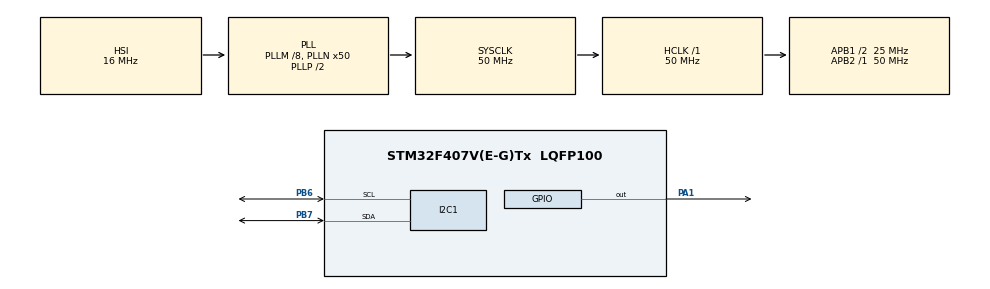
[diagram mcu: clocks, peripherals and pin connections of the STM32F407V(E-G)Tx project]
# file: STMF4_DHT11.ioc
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Mcu.Family=STM32F4
Mcu.Name=STM32F407V(E-G)Tx
Mcu.Package=LQFP100
NVIC.PriorityGroup=NVIC_PRIORITYGROUP_4
PA1.Signal=GPIO_Output
PB6.Mode=I2C
PB6.Signal=I2C1_SCL
PB7.Mode=I2C
PB7.Signal=I2C1_SDA
PH0-OSC_IN.Mode=HSE-External-Oscillator
PH0-OSC_IN.Signal=RCC_OSC_IN
PH1-OSC_OUT.Mode=HSE-External-Oscillator
PH1-OSC_OUT.Signal=RCC_OSC_OUT
ProjectManager.HeapSize=0x200
ProjectManager.StackSize=0x400
ProjectManager.TargetToolchain=MDK-ARM V5.32
RCC.48MHZClocksFreq_Value=25000000
RCC.AHBFreq_Value=50000000
RCC.APB1CLKDivider=RCC_HCLK_DIV2
RCC.APB1Freq_Value=25000000
RCC.APB1TimFreq_Value=50000000
RCC.APB2Freq_Value=50000000
RCC.APB2TimFreq_Value=50000000
RCC.CortexFreq_Value=50000000
RCC.HCLKFreq_Value=50000000
RCC.HSE_VALUE=8000000
RCC.HSI_VALUE=16000000
RCC.PLLM=8
RCC.PLLN=50
RCC.SYSCLKFreq_VALUE=50000000
RCC.SYSCLKSource=RCC_SYSCLKSOURCE_PLLCLK
RCC.VCOOutputFreq_Value=100000000
TIM6.Period=0xffff-1
TIM6.Prescaler=50-1
VP_TIM6_VS_ClockSourceINT.Mode=Enable_Timer
board=custom

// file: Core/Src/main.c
/* USER CODE BEGIN Header */
/**
  ******************************************************************************
  * @file           : main.c
  * @brief          : Main program body
  ******************************************************************************
  * @attention
  *
  * Copyright (c) 2023 STMicroelectronics.
  * All rights reserved.
  *
  * This software is licensed under terms that can be found in the LICENSE file
  * in the root directory of this software component.
  * If no LICENSE file comes with this software, it is provided AS-IS.
  *
  ******************************************************************************
  */
/* USER CODE END Header */
#include "main.h"

/* USER CODE BEGIN Includes */

#include "stdio.h"
/* USER CODE END Includes */

I2C_HandleTypeDef hi2c1;

TIM_HandleTypeDef htim6;

void SystemClock_Config(void);
static void MX_GPIO_Init(void);
static void MX_TIM6_Init(void);
static void MX_I2C1_Init(void);

/* USER CODE BEGIN 0 */

void delay (uint16_t t )
	{
	//Fonction delay en micro secondes
	__HAL_TIM_SET_COUNTER(&htim6, 0);
	while((__HAL_TIM_GET_COUNTER(&htim6))< t);
}

uint8_t rh_byte1, rh_byte2, temp_byte1, temp_byte2;
uint16_t sum, rh, temp;

float temperature = 0;
float humidity = 0;
uint8_t presence =0;

void Set_Pin_Output (GPIO_TypeDef *GPIOx, uint16_t GPIO_Pin)
{
	GPIO_InitTypeDef GPIO_InitStruct = {0};
	GPIO_InitStruct.Pin = GPIO_Pin;
	GPIO_InitStruct.Mode = GPIO_MODE_OUTPUT_PP;
	GPIO_InitStruct.Speed = GPIO_SPEED_FREQ_LOW;
	HAL_GPIO_Init(GPIOx, &GPIO_InitStruct);
}
void Set_Pin_Input (GPIO_TypeDef *GPIOx, uint16_t GPIO_Pin)
{
	GPIO_InitTypeDef GPIO_InitStruct = {0};
	GPIO_InitStruct.Pin = GPIO_Pin;
	GPIO_InitStruct.Mode = GPIO_MODE_INPUT;
	GPIO_InitStruct.Pull = GPIO_NOPULL;
	//CHANGE TO PULLUP if wrong
	HAL_GPIO_Init(GPIOx, &GPIO_InitStruct);
}

/**************************************DHT Communication function ****************************/
#define DHT22_PORT GPIOA
#define DHT22_PIN GPIO_PIN_1
//START COMM
void DHT22_Start (void)
{
	Set_Pin_Output(DHT22_PORT, DHT22_PIN); // set the pin as output
	HAL_GPIO_WritePin (DHT22_PORT, DHT22_PIN, 0);   // pull the pin low
	delay(1200);   // wait for > 1ms

	HAL_GPIO_WritePin (DHT22_PORT, DHT22_PIN, 1);   // pull the pin high
	delay (20);   // wait for 30us

	Set_Pin_Input(DHT22_PORT, DHT22_PIN);   // set as input
}
//CHECK RESPONSE
// the response is LOW for 80 us and then HIGH for 80 us
uint8_t DHT22_Check_Response (void)
{
	Set_Pin_Input(DHT22_PORT, DHT22_PIN);   // set as input
	uint8_t Response = 0;
	delay (40);  // wait for 40us
	if (!(HAL_GPIO_ReadPin (DHT22_PORT, DHT22_PIN))) // if the pin is low
	{
		delay (80);   // wait for 80us

		if ((HAL_GPIO_ReadPin (DHT22_PORT, DHT22_PIN))) Response = 1;  // if the pin is high, response is ok
		else Response = -1;
	}

	while ((HAL_GPIO_ReadPin (DHT22_PORT, DHT22_PIN)));   // wait for the pin to go low
	return Response;
}
//READ DATA
uint8_t DHT22_Read (void)
{
	uint8_t i,j;
	for (j=0;j<8;j++)
	{
		while (!(HAL_GPIO_ReadPin (DHT22_PORT, DHT22_PIN)));   // wait for the pin to go high
		delay (40);   // wait for 40 us

		if (!(HAL_GPIO_ReadPin (DHT22_PORT, DHT22_PIN)))   // if the pin is low
		{
			i&= ~(1<<(7-j));   // write 0
		}
		else i|= (1<<(7-j));  // if the pin is high, write 1
		while ((HAL_GPIO_ReadPin (DHT22_PORT, DHT22_PIN)));  // wait for the pin to go low
	}

	return i;
}
/*
#define DHT11_PORT GPIOA
#define DHT11_PIN GPIO_PIN_1

void DHT11_Start ()
{
	Set_Pin_Output ( DHT11_PORT, DHT11_PIN);
	HAL_GPIO_WritePin (DHT11_PORT,DHT11_PIN,0);
	delay(18000); //Pulling the data line low for 18ms
	HAL_GPIO_WritePin (DHT11_PORT,DHT11_PIN,1);
	delay(20); //waiting for 20 to 40 us
	Set_Pin_Input( DHT11_PORT, DHT11_PIN);
}

uint8_t DHT11_Check_Response ()
{
	uint8_t Response = 0;
	delay(40);
	if(!(HAL_GPIO_ReadPin(DHT11_PORT,DHT11_PIN)))
	{
		delay (80);
		if((HAL_GPIO_ReadPin (DHT11_PORT,DHT11_PIN))) Response =1;
		else Response = -1;
	}
	while ((HAL_GPIO_ReadPin(DHT11_PORT,DHT11_PIN)));
	//Data can begin
	return Response;
}

uint8_t DHT11_Read()
{
	uint8_t data,i;
	for(i=0;i<8;i++)
	{
		while (!(HAL_GPIO_ReadPin (DHT11_PORT, DHT11_PIN)));
		delay(40);
		if (!(HAL_GPIO_ReadPin (DHT11_PORT, DHT11_PIN)))
		{
			data&= ~(1<<(7-i)); //write 0
		}
		else data|= (1<<(7-i)); //write 1
		while((HAL_GPIO_ReadPin (DHT11_PORT, DHT11_PIN)));
	}
	return data;
}
*/

/* USER CODE END 0 */

int main(void)
{

  /* MCU Configuration--------------------------------------------------------*/

  /* Reset of all peripherals, Initializes the Flash interface and the Systick. */
  HAL_Init();

  /* Configure the system clock */
  SystemClock_Config();

  /* Initialize all configured peripherals */
  MX_GPIO_Init();
  MX_TIM6_Init();
  MX_I2C1_Init();
  /* USER CODE BEGIN 2 */

  HAL_TIM_Base_Start(&htim6);

  /* USER CODE END 2 */

  /* Infinite loop */
  while (1)
  {
	  DHT22_Start();
	  presence = DHT22_Check_Response();
	  if (presence == 1)
	  {
	  rh_byte1 = DHT22_Read ();
	  rh_byte2 = DHT22_Read ();
	  temp_byte1 = DHT22_Read ();
	  temp_byte2 = DHT22_Read ();
	  sum = DHT22_Read();

	  temp = ((temp_byte1<<8)|temp_byte2);
	  rh = ((rh_byte1<<8)|rh_byte2);

	  temperature = (float) (temp/10.0);
	  humidity = (float) (rh/10.0);
	  } else
	  {
		  temperature = -1.0;
		  humidity = -1.0;
	  }
  }
}

void SystemClock_Config(void)
{
  RCC_OscInitTypeDef RCC_OscInitStruct = {0};
  RCC_ClkInitTypeDef RCC_ClkInitStruct = {0};

  /** Configure the main internal regulator output voltage
  */
  __HAL_RCC_PWR_CLK_ENABLE();
  __HAL_PWR_VOLTAGESCALING_CONFIG(PWR_REGULATOR_VOLTAGE_SCALE1);

  /** Initializes the RCC Oscillators according to the specified parameters
  * in the RCC_OscInitTypeDef structure.
  */
  RCC_OscInitStruct.OscillatorType = RCC_OSCILLATORTYPE_HSI;
  RCC_OscInitStruct.HSIState = RCC_HSI_ON;
  RCC_OscInitStruct.HSICalibrationValue = RCC_HSICALIBRATION_DEFAULT;
  RCC_OscInitStruct.PLL.PLLState = RCC_PLL_ON;
  RCC_OscInitStruct.PLL.PLLSource = RCC_PLLSOURCE_HSI;
  RCC_OscInitStruct.PLL.PLLM = 8;
  RCC_OscInitStruct.PLL.PLLN = 50;
  RCC_OscInitStruct.PLL.PLLP = RCC_PLLP_DIV2;
  RCC_OscInitStruct.PLL.PLLQ = 4;
  if (HAL_RCC_OscConfig(&RCC_OscInitStruct) != HAL_OK)
  {
    Error_Handler();
  }

  /** Initializes the CPU, AHB and APB buses clocks
  */
  RCC_ClkInitStruct.ClockType = RCC_CLOCKTYPE_HCLK|RCC_CLOCKTYPE_SYSCLK
                              |RCC_CLOCKTYPE_PCLK1|RCC_CLOCKTYPE_PCLK2;
  RCC_ClkInitStruct.SYSCLKSource = RCC_SYSCLKSOURCE_PLLCLK;
  RCC_ClkInitStruct.AHBCLKDivider = RCC_SYSCLK_DIV1;
  RCC_ClkInitStruct.APB1CLKDivider = RCC_HCLK_DIV2;
  RCC_ClkInitStruct.APB2CLKDivider = RCC_HCLK_DIV1;

  if (HAL_RCC_ClockConfig(&RCC_ClkInitStruct, FLASH_LATENCY_1) != HAL_OK)
  {
    Error_Handler();
  }
}

static void MX_I2C1_Init(void)
{

  hi2c1.Instance = I2C1;
  hi2c1.Init.ClockSpeed = 100000;
  hi2c1.Init.DutyCycle = I2C_DUTYCYCLE_2;
  hi2c1.Init.OwnAddress1 = 0;
  hi2c1.Init.AddressingMode = I2C_ADDRESSINGMODE_7BIT;
  hi2c1.Init.DualAddressMode = I2C_DUALADDRESS_DISABLE;
  hi2c1.Init.OwnAddress2 = 0;
  hi2c1.Init.GeneralCallMode = I2C_GENERALCALL_DISABLE;
  hi2c1.Init.NoStretchMode = I2C_NOSTRETCH_DISABLE;
  if (HAL_I2C_Init(&hi2c1) != HAL_OK)
  {
    Error_Handler();
  }

}

static void MX_TIM6_Init(void)
{

  TIM_MasterConfigTypeDef sMasterConfig = {0};

  htim6.Instance = TIM6;
  htim6.Init.Prescaler = 50-1;
  htim6.Init.CounterMode = TIM_COUNTERMODE_UP;
  htim6.Init.Period = 0xffff-1;
  htim6.Init.AutoReloadPreload = TIM_AUTORELOAD_PRELOAD_DISABLE;
  if (HAL_TIM_Base_Init(&htim6) != HAL_OK)
  {
    Error_Handler();
  }
  sMasterConfig.MasterOutputTrigger = TIM_TRGO_RESET;
  sMasterConfig.MasterSlaveMode = TIM_MASTERSLAVEMODE_DISABLE;
  if (HAL_TIMEx_MasterConfigSynchronization(&htim6, &sMasterConfig) != HAL_OK)
  {
    Error_Handler();
  }

}

static void MX_GPIO_Init(void)
{
  GPIO_InitTypeDef GPIO_InitStruct = {0};

  /* GPIO Ports Clock Enable */
  __HAL_RCC_GPIOH_CLK_ENABLE();
  __HAL_RCC_GPIOA_CLK_ENABLE();
  __HAL_RCC_GPIOB_CLK_ENABLE();

  /*Configure GPIO pin Output Level */
  HAL_GPIO_WritePin(GPIOA, GPIO_PIN_1, GPIO_PIN_RESET);

  /*Configure GPIO pin : PA1 */
  GPIO_InitStruct.Pin = GPIO_PIN_1;
  GPIO_InitStruct.Mode = GPIO_MODE_OUTPUT_PP;
  GPIO_InitStruct.Pull = GPIO_NOPULL;
  GPIO_InitStruct.Speed = GPIO_SPEED_FREQ_LOW;
  HAL_GPIO_Init(GPIOA, &GPIO_InitStruct);

}

void Error_Handler(void)
{
  __disable_irq();
  while (1)
  {
  }
}
